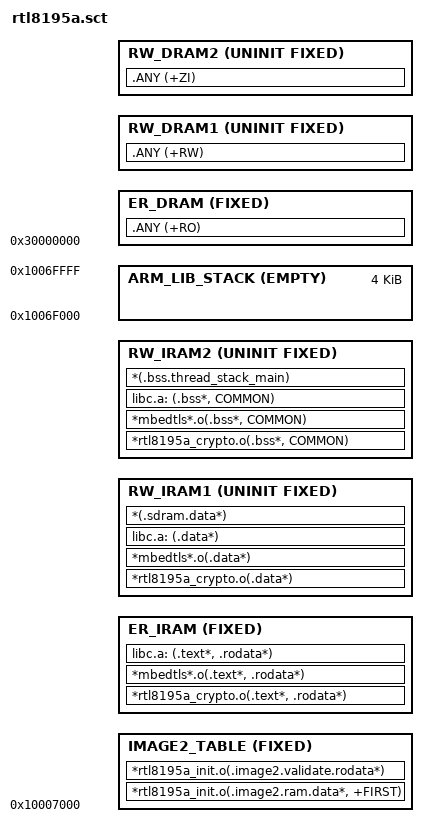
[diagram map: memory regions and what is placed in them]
; Realtek Semiconductor Corp.
;
; RTL8195A ARMCC Scatter File
;
; MEMORY
; {
;   SROM (rx)    : ORIGIN = 0x10000000, LENGTH = 0x00007000
;   SRAM (rwx)   : ORIGIN = 0x10007000, LENGTH = 0x00070000 - 0x00007000
;   TCM  (rwx)   : ORIGIN = 0x1FFF0000, LENGTH = 0x00010000
;   DRAM (rwx)   : ORIGIN = 0x30000000, LENGTH = 2M
; }

LR_IRAM 0x10007000 (0x70000 - 0x7000) {

  IMAGE2_TABLE 0x10007000 FIXED {
    *rtl8195a_init.o(.image2.ram.data*, +FIRST)
    *rtl8195a_init.o(.image2.validate.rodata*)
  }

  ER_IRAM +0 FIXED {
    *rtl8195a_crypto.o(.text*, .rodata*)
    *mbedtls*.o(.text*, .rodata*)
    libc.a: (.text*, .rodata*)
  }

  RW_IRAM1 +0 UNINIT FIXED {
    *rtl8195a_crypto.o(.data*)
    *mbedtls*.o(.data*)
    libc.a: (.data*)
    *(.sdram.data*)
  }

  RW_IRAM2 +0 UNINIT FIXED {
    *rtl8195a_crypto.o(.bss*, COMMON)
    *mbedtls*.o(.bss*, COMMON)
    libc.a: (.bss*, COMMON)
    *(.bss.thread_stack_main)
  }

  ARM_LIB_STACK (0x10070000 - 0x1000) EMPTY 0x1000 {
  }
}

LR_DRAM 0x30000000 0x200000 {

  ER_DRAM +0 FIXED {
    .ANY (+RO)
  }

  RW_DRAM1 +0 UNINIT FIXED {
   .ANY (+RW)
  }

  RW_DRAM2 +0 UNINIT FIXED {
   .ANY (+ZI)
  }
}
